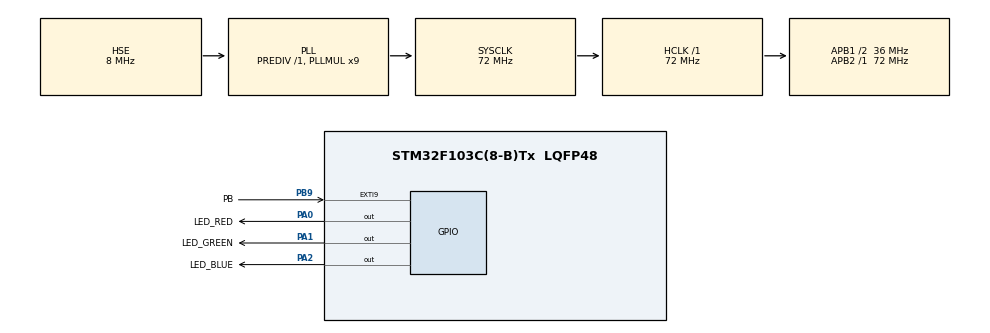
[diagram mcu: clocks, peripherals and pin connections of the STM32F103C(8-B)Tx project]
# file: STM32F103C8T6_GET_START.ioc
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Dma.MEMTOMEM.0.Direction=DMA_MEMORY_TO_MEMORY
Dma.MEMTOMEM.0.Instance=DMA1_Channel1
Dma.MEMTOMEM.0.MemDataAlignment=DMA_MDATAALIGN_BYTE
Dma.MEMTOMEM.0.MemInc=DMA_MINC_ENABLE
Dma.MEMTOMEM.0.Mode=DMA_NORMAL
Dma.MEMTOMEM.0.PeriphDataAlignment=DMA_PDATAALIGN_BYTE
Dma.MEMTOMEM.0.PeriphInc=DMA_PINC_ENABLE
Dma.MEMTOMEM.0.Priority=DMA_PRIORITY_LOW
Dma.Request0=MEMTOMEM
Mcu.Family=STM32F1
Mcu.Name=STM32F103C(8-B)Tx
Mcu.Package=LQFP48
NVIC.DMA1_Channel1_IRQn=true\:0\:0\:false\:false\:true\:true\:true\:true
NVIC.EXTI9_5_IRQn=true\:1\:0\:true\:false\:true\:true\:true\:true
NVIC.PriorityGroup=NVIC_PRIORITYGROUP_4
PA0-WKUP.GPIO_Label=LED_RED
PA0-WKUP.GPIO_Speed=GPIO_SPEED_FREQ_HIGH
PA0-WKUP.PinState=GPIO_PIN_SET
PA0-WKUP.Signal=GPIO_Output
PA1.GPIO_Label=LED_GREEN
PA1.GPIO_Speed=GPIO_SPEED_FREQ_HIGH
PA1.PinState=GPIO_PIN_SET
PA1.Signal=GPIO_Output
PA13.Mode=Serial_Wire
PA13.Signal=SYS_JTMS-SWDIO
PA14.Mode=Serial_Wire
PA14.Signal=SYS_JTCK-SWCLK
PA2.GPIO_Label=LED_BLUE
PA2.GPIO_Speed=GPIO_SPEED_FREQ_HIGH
PA2.PinState=GPIO_PIN_SET
PA2.Signal=GPIO_Output
PB9.GPIO_Label=PB
PB9.Signal=GPXTI9
PC14-OSC32_IN.Mode=LSE-External-Oscillator
PC14-OSC32_IN.Signal=RCC_OSC32_IN
PC15-OSC32_OUT.Mode=LSE-External-Oscillator
PC15-OSC32_OUT.Signal=RCC_OSC32_OUT
PD0-OSC_IN.Mode=HSE-External-Oscillator
PD0-OSC_IN.Signal=RCC_OSC_IN
PD1-OSC_OUT.Mode=HSE-External-Oscillator
PD1-OSC_OUT.Signal=RCC_OSC_OUT
ProjectManager.HeapSize=0x200
ProjectManager.StackSize=0x400
ProjectManager.TargetToolchain=STM32CubeIDE
RCC.AHBFreq_Value=72000000
RCC.APB1CLKDivider=RCC_HCLK_DIV2
RCC.APB1Freq_Value=36000000
RCC.APB1TimFreq_Value=72000000
RCC.APB2Freq_Value=72000000
RCC.APB2TimFreq_Value=72000000
RCC.HCLKFreq_Value=72000000
RCC.PLLMUL=RCC_PLL_MUL9
RCC.PLLSourceVirtual=RCC_PLLSOURCE_HSE
RCC.SYSCLKFreq_VALUE=72000000
RCC.SYSCLKSource=RCC_SYSCLKSOURCE_PLLCLK
RCC.USBFreq_Value=72000000
board=custom

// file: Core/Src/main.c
/* USER CODE BEGIN Header */
/**
  ******************************************************************************
  * @file           : main.c
  * @brief          : Main program body
  ******************************************************************************
  * @attention
  *
  * Copyright (c) 2026 STMicroelectronics.
  * All rights reserved.
  *
  * This software is licensed under terms that can be found in the LICENSE file
  * in the root directory of this software component.
  * If no LICENSE file comes with this software, it is provided AS-IS.
  *
  ******************************************************************************
  */
/* USER CODE END Header */
#include "main.h"

DMA_HandleTypeDef hdma_memtomem_dma1_channel1;
/* USER CODE BEGIN PV */
const int my_array[10];
/* USER CODE END PV */

void SystemClock_Config(void);
static void MX_GPIO_Init(void);
static void MX_DMA_Init(void);

int main(void)
{

  /* MCU Configuration--------------------------------------------------------*/

  /* Reset of all peripherals, Initializes the Flash interface and the Systick. */
  HAL_Init();

  /* Configure the system clock */
  SystemClock_Config();

  /* Initialize all configured peripherals */
  MX_GPIO_Init();
  MX_DMA_Init();

  /* Infinite loop */
  while (1)
  {

  }
}

void SystemClock_Config(void)
{
  RCC_OscInitTypeDef RCC_OscInitStruct = {0};
  RCC_ClkInitTypeDef RCC_ClkInitStruct = {0};

  /** Initializes the RCC Oscillators according to the specified parameters
  * in the RCC_OscInitTypeDef structure.
  */
  RCC_OscInitStruct.OscillatorType = RCC_OSCILLATORTYPE_HSE;
  RCC_OscInitStruct.HSEState = RCC_HSE_ON;
  RCC_OscInitStruct.HSEPredivValue = RCC_HSE_PREDIV_DIV1;
  RCC_OscInitStruct.HSIState = RCC_HSI_ON;
  RCC_OscInitStruct.PLL.PLLState = RCC_PLL_ON;
  RCC_OscInitStruct.PLL.PLLSource = RCC_PLLSOURCE_HSE;
  RCC_OscInitStruct.PLL.PLLMUL = RCC_PLL_MUL9;
  if (HAL_RCC_OscConfig(&RCC_OscInitStruct) != HAL_OK)
  {
    Error_Handler();
  }

  /** Initializes the CPU, AHB and APB buses clocks
  */
  RCC_ClkInitStruct.ClockType = RCC_CLOCKTYPE_HCLK|RCC_CLOCKTYPE_SYSCLK
                              |RCC_CLOCKTYPE_PCLK1|RCC_CLOCKTYPE_PCLK2;
  RCC_ClkInitStruct.SYSCLKSource = RCC_SYSCLKSOURCE_PLLCLK;
  RCC_ClkInitStruct.AHBCLKDivider = RCC_SYSCLK_DIV1;
  RCC_ClkInitStruct.APB1CLKDivider = RCC_HCLK_DIV2;
  RCC_ClkInitStruct.APB2CLKDivider = RCC_HCLK_DIV1;

  if (HAL_RCC_ClockConfig(&RCC_ClkInitStruct, FLASH_LATENCY_2) != HAL_OK)
  {
    Error_Handler();
  }
}

static void MX_DMA_Init(void)
{

  /* DMA controller clock enable */
  __HAL_RCC_DMA1_CLK_ENABLE();

  /* Configure DMA request hdma_memtomem_dma1_channel1 on DMA1_Channel1 */
  hdma_memtomem_dma1_channel1.Instance = DMA1_Channel1;
  hdma_memtomem_dma1_channel1.Init.Direction = DMA_MEMORY_TO_MEMORY;
  hdma_memtomem_dma1_channel1.Init.PeriphInc = DMA_PINC_ENABLE;
  hdma_memtomem_dma1_channel1.Init.MemInc = DMA_MINC_ENABLE;
  hdma_memtomem_dma1_channel1.Init.PeriphDataAlignment = DMA_PDATAALIGN_BYTE;
  hdma_memtomem_dma1_channel1.Init.MemDataAlignment = DMA_MDATAALIGN_BYTE;
  hdma_memtomem_dma1_channel1.Init.Mode = DMA_NORMAL;
  hdma_memtomem_dma1_channel1.Init.Priority = DMA_PRIORITY_LOW;
  if (HAL_DMA_Init(&hdma_memtomem_dma1_channel1) != HAL_OK)
  {
    Error_Handler( );
  }

  /* DMA interrupt init */
  /* DMA1_Channel1_IRQn interrupt configuration */
  HAL_NVIC_SetPriority(DMA1_Channel1_IRQn, 0, 0);
  HAL_NVIC_EnableIRQ(DMA1_Channel1_IRQn);

}

static void MX_GPIO_Init(void)
{
  GPIO_InitTypeDef GPIO_InitStruct = {0};

  /* GPIO Ports Clock Enable */
  __HAL_RCC_GPIOC_CLK_ENABLE();
  __HAL_RCC_GPIOD_CLK_ENABLE();
  __HAL_RCC_GPIOA_CLK_ENABLE();
  __HAL_RCC_GPIOB_CLK_ENABLE();

  /*Configure GPIO pin Output Level */
  HAL_GPIO_WritePin(GPIOA, LED_RED_Pin|LED_GREEN_Pin|LED_BLUE_Pin, GPIO_PIN_SET);

  /*Configure GPIO pins : LED_RED_Pin LED_GREEN_Pin LED_BLUE_Pin */
  GPIO_InitStruct.Pin = LED_RED_Pin|LED_GREEN_Pin|LED_BLUE_Pin;
  GPIO_InitStruct.Mode = GPIO_MODE_OUTPUT_PP;
  GPIO_InitStruct.Pull = GPIO_NOPULL;
  GPIO_InitStruct.Speed = GPIO_SPEED_FREQ_HIGH;
  HAL_GPIO_Init(GPIOA, &GPIO_InitStruct);

  /*Configure GPIO pin : PB_Pin */
  GPIO_InitStruct.Pin = PB_Pin;
  GPIO_InitStruct.Mode = GPIO_MODE_IT_RISING;
  GPIO_InitStruct.Pull = GPIO_NOPULL;
  HAL_GPIO_Init(PB_GPIO_Port, &GPIO_InitStruct);

  /* EXTI interrupt init*/
  HAL_NVIC_SetPriority(EXTI9_5_IRQn, 1, 0);
  HAL_NVIC_EnableIRQ(EXTI9_5_IRQn);

}

/* USER CODE BEGIN 4 */

void HAL_GPIO_EXTI_Callback(uint16_t GPIO_Pin)
{
	if (GPIO_Pin == PB_Pin)
	{
		HAL_GPIO_TogglePin(GPIOA, LED_RED_Pin|LED_GREEN_Pin|LED_BLUE_Pin);
	}
}

/* USER CODE END 4 */

void Error_Handler(void)
{
  __disable_irq();
  while (1)
  {
  }
}
